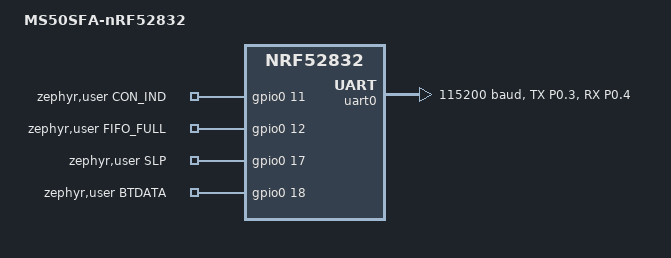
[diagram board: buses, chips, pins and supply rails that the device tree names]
// Copyright (c) 2024 Nordic Semiconductor ASA
// SPDX-License-Identifier: Apache-2.0

/dts-v1/;
#include <nordic/nrf52832_qfaa.dtsi>

/ {
	model = "MS50SFA-nRF52832";
	compatible = "ms50sfa-nrf52832";

	chosen {
		zephyr,sram = &sram0;
		zephyr,flash = &flash0;
		zephyr,code-partition = &slot0_partition;
		zephyr,console = &uart0;
		zephyr,shell-uart = &uart0;
	};

	zephyr,user {
		CON_IND-gpios = <&gpio0 11 0>;
		FIFO_FULL-gpios = <&gpio0 12 0>;
		SLP-gpios = <&gpio0 17 0>;
		BTDATA-gpios = <&gpio0 18 0>;
	};
};

&flash0 {
	partitions {
		compatible = "fixed-partitions";
		#address-cells = <1>;
		#size-cells = <1>;

		boot_partition: partition@0 {
			label = "mcuboot";
			reg = <0x0 0xc000>;
		};
		slot0_partition: partition@c000 {
			label = "image-0";
			reg = <0xc000 0x32000>;
		};
		slot1_partition: partition@3e000 {
			label = "image-1";
			reg = <0x3e000 0x32000>;
		};
		scratch_partition: partition@70000 {
			label = "image-scratch";
			reg = <0x70000 0xa000>;
		};
		storage_partition: partition@7a000 {
			label = "storage";
			reg = <0x7a000 0x6000>;
		};
	};
};

&uicr {
	gpio-as-nreset;
};

&gpiote {
	status = "okay";
};

&gpio0 {
	status = "okay";
};

&uart0 {
	status = "okay";
	current-speed = <115200>;
	pinctrl-0 = <&uart0_default>;
	pinctrl-names = "default";
};

&pinctrl {
	uart0_default: uart0_default {
		group1 {
			psels = <NRF_PSEL(UART_TX, 0, 3)>, <NRF_PSEL(UART_RX, 0, 4)>;
		};
	};
};
